VERSION "DNNBNNNYNNNNNNNNNNNNNNNNNNYYYNNNNNNNNNNNNN/4/%%%/4/'%**4NNN///"

NS_ :

BS_:

BU_:  TLCU_L TLCU_R HLCU_R HLCU_L SWCU VCU BCU_F IVI

BO_ 2017 BODY_HLCU_R_UDS_RESP: 8 HLCU_R
 SG_ HLCU_R_uds_resp : 7|64@0+ (1,0) [0|255] ""  IVI

BO_ 2016 BODY_HLCU_R_UDS_REQ: 8 IVI
 SG_ HLCU_R_uds_req : 7|64@0+ (1,0) [0|255] ""  HLCU_R

BO_ 2015 BODY_HLCU_L_UDS_RESP: 8 HLCU_L
 SG_ HLCU_L_uds_resp : 7|64@0+ (1,0) [0|255] ""  IVI

BO_ 2014 BODY_HLCU_L_UDS_REQ: 8 IVI
 SG_ HLCU_L_uds_req : 7|64@0+ (1,0) [0|255] ""  HLCU_L

BO_ 2013 BODY_TLCU_R_UDS_RESP: 8 TLCU_R
 SG_ TLCU_R_uds_resp : 7|64@0+ (1,0) [0|255] ""  IVI

BO_ 2012 BODY_TLCU_R_UDS_REQ: 8 IVI
 SG_ TLCU_R_uds_req : 7|64@0+ (1,0) [0|255] ""  TLCU_R

BO_ 2011 BODY_TLCU_L_UDS_RESP: 8 TLCU_L
 SG_ TLCU_L_uds_resp : 7|64@0+ (1,0) [0|255] ""  IVI

BO_ 2010 BODY_TLCU_L_UDS_REQ: 8 IVI
 SG_ TLCU_L_uds_req : 7|64@0+ (1,0) [0|255] ""  TLCU_L

BO_ 2009 BODY_SWCU_UDS_RESP: 8 SWCU
 SG_ SWCU_uds_resp : 7|64@0+ (1,0) [0|255] ""  IVI

BO_ 2008 BODY_SWCU_UDS_REQ: 8 IVI
 SG_ SWCU_uds_req : 7|64@0+ (1,0) [0|255] ""  SWCU

BO_ 1997 BODY_BCU_F_UDS_RESP: 8 BCU_F
 SG_ BCU_F_uds_resp : 7|64@0+ (1,0) [0|255] ""  IVI

BO_ 1996 BODY_BCU_F_UDS_REQ: 8 IVI
 SG_ BCU_F_uds_req : 7|64@0+ (1,0) [0|255] ""  BCU_F

BO_ 1987 BODY_IVI_UDS_RESP: 8 IVI
 SG_ IVI_uds_resp : 7|64@0+ (1,0) [0|255] ""  IVI

BO_ 1986 BODY_IVI_UDS_REQ: 8 IVI
 SG_ IVI_uds_req : 7|64@0+ (1,0) [0|255] ""  IVI

BO_ 1985 BODY_VCU_UDS_RESP: 8 VCU
 SG_ VCU_uds_resp : 7|64@0+ (1,0) [0|255] ""  IVI

BO_ 1984 BODY_VCU_UDS_REQ: 8 IVI
 SG_ VCU_uds_req : 7|64@0+ (1,0) [0|255] ""  VCU

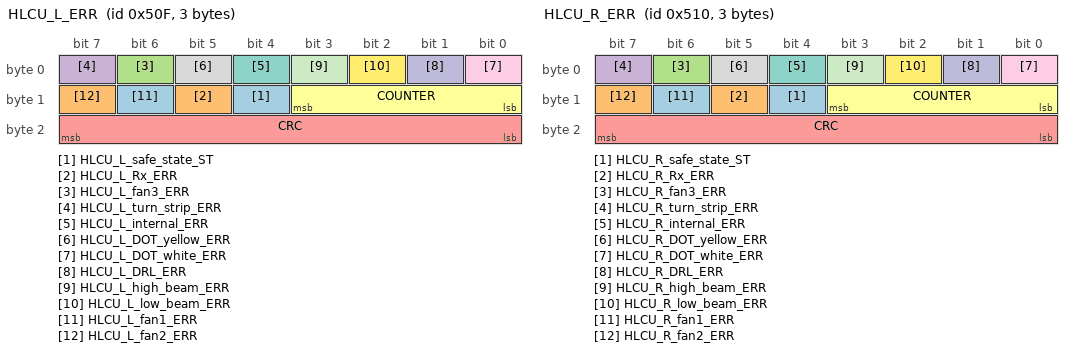
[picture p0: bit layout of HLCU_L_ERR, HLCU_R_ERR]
BO_ 1295 HLCU_L_ERR: 3 HLCU_L
 SG_ HLCU_L_safe_state_ST : 12|1@0+ (1,0) [0|1] ""  VCU,BCU_F
 SG_ HLCU_L_Rx_ERR : 13|1@0+ (1,0) [0|3] ""  VCU,BCU_F
 SG_ HLCU_L_fan3_ERR : 6|1@0+ (1,0) [0|3] ""  VCU,BCU_F
 SG_ HLCU_L_turn_strip_ERR : 7|1@0+ (1,0) [0|3] ""  VCU,BCU_F,IVI
 SG_ CRC : 23|8@0+ (1,0) [0|255] ""  VCU,BCU_F,IVI
 SG_ COUNTER : 11|4@0+ (1,0) [0|15] ""  VCU,BCU_F,IVI
 SG_ HLCU_L_internal_ERR : 4|1@0+ (1,0) [0|3] ""  VCU,BCU_F
 SG_ HLCU_L_DOT_yellow_ERR : 5|1@0+ (1,0) [0|3] ""  VCU,BCU_F,IVI
 SG_ HLCU_L_DOT_white_ERR : 0|1@0+ (1,0) [0|3] ""  VCU,BCU_F
 SG_ HLCU_L_DRL_ERR : 1|1@0+ (1,0) [0|3] ""  VCU,BCU_F
 SG_ HLCU_L_high_beam_ERR : 3|1@0+ (1,0) [0|3] ""  VCU,BCU_F
 SG_ HLCU_L_low_beam_ERR : 2|1@0+ (1,0) [0|3] ""  VCU,BCU_F
 SG_ HLCU_L_fan1_ERR : 14|1@0+ (1,0) [0|3] ""  VCU,BCU_F
 SG_ HLCU_L_fan2_ERR : 15|1@0+ (1,0) [0|3] ""  VCU,BCU_F

BO_ 1296 HLCU_R_ERR: 3 HLCU_R
 SG_ HLCU_R_safe_state_ST : 12|1@0+ (1,0) [0|1] ""  VCU,BCU_F
 SG_ HLCU_R_Rx_ERR : 13|1@0+ (1,0) [0|3] ""  VCU,BCU_F
 SG_ HLCU_R_fan3_ERR : 6|1@0+ (1,0) [0|3] ""  VCU,BCU_F
 SG_ HLCU_R_turn_strip_ERR : 7|1@0+ (1,0) [0|3] ""  VCU,BCU_F,IVI
 SG_ CRC : 23|8@0+ (1,0) [0|255] ""  VCU,BCU_F,IVI
 SG_ COUNTER : 11|4@0+ (1,0) [0|15] ""  VCU,BCU_F,IVI
 SG_ HLCU_R_internal_ERR : 4|1@0+ (1,0) [0|3] ""  VCU,BCU_F
 SG_ HLCU_R_DOT_yellow_ERR : 5|1@0+ (1,0) [0|3] ""  VCU,BCU_F,IVI
 SG_ HLCU_R_DOT_white_ERR : 0|1@0+ (1,0) [0|3] ""  VCU,BCU_F
 SG_ HLCU_R_DRL_ERR : 1|1@0+ (1,0) [0|3] ""  VCU,BCU_F
 SG_ HLCU_R_high_beam_ERR : 3|1@0+ (1,0) [0|3] ""  VCU,BCU_F
 SG_ HLCU_R_low_beam_ERR : 2|1@0+ (1,0) [0|3] ""  VCU,BCU_F
 SG_ HLCU_R_fan1_ERR : 14|1@0+ (1,0) [0|3] ""  VCU,BCU_F
 SG_ HLCU_R_fan2_ERR : 15|1@0+ (1,0) [0|3] ""  VCU,BCU_F

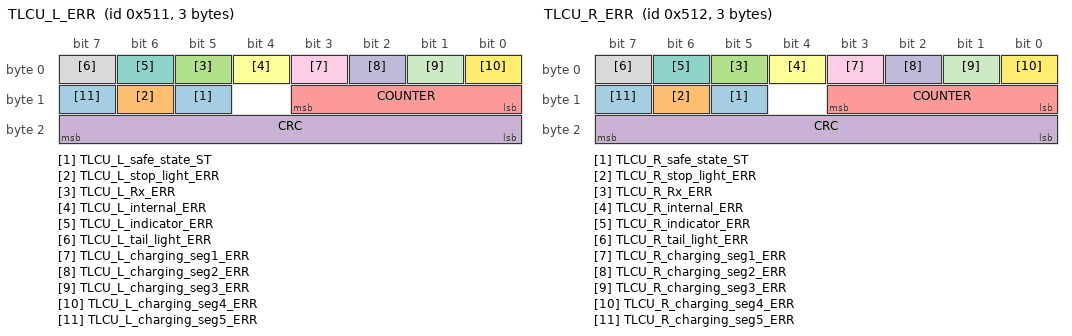
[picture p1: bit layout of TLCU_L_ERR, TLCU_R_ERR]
BO_ 1297 TLCU_L_ERR: 3 TLCU_L
 SG_ TLCU_L_safe_state_ST : 13|1@0+ (1,0) [0|0] ""  VCU,BCU_F
 SG_ TLCU_L_stop_light_ERR : 14|1@0+ (1,0) [0|3] ""  VCU,BCU_F
 SG_ TLCU_L_Rx_ERR : 5|1@0+ (1,0) [0|3] ""  VCU,BCU_F
 SG_ CRC : 23|8@0+ (1,0) [0|255] ""  VCU,BCU_F,IVI
 SG_ COUNTER : 11|4@0+ (1,0) [0|15] ""  VCU,BCU_F,IVI
 SG_ TLCU_L_internal_ERR : 4|1@0+ (1,0) [0|3] ""  VCU,BCU_F
 SG_ TLCU_L_indicator_ERR : 6|1@0+ (1,0) [0|3] ""  VCU,BCU_F,IVI
 SG_ TLCU_L_tail_light_ERR : 7|1@0+ (1,0) [0|3] ""  VCU,BCU_F
 SG_ TLCU_L_charging_seg1_ERR : 3|1@0+ (1,0) [0|3] ""  VCU,BCU_F
 SG_ TLCU_L_charging_seg2_ERR : 2|1@0+ (1,0) [0|3] ""  VCU,BCU_F
 SG_ TLCU_L_charging_seg3_ERR : 1|1@0+ (1,0) [0|3] ""  VCU,BCU_F
 SG_ TLCU_L_charging_seg4_ERR : 0|1@0+ (1,0) [0|3] ""  VCU,BCU_F
 SG_ TLCU_L_charging_seg5_ERR : 15|1@0+ (1,0) [0|3] ""  VCU,BCU_F

BO_ 1298 TLCU_R_ERR: 3 TLCU_R
 SG_ TLCU_R_safe_state_ST : 13|1@0+ (1,0) [0|1] ""  VCU,BCU_F
 SG_ TLCU_R_stop_light_ERR : 14|1@0+ (1,0) [0|3] ""  VCU,BCU_F
 SG_ TLCU_R_Rx_ERR : 5|1@0+ (1,0) [0|3] ""  VCU,BCU_F
 SG_ CRC : 23|8@0+ (1,0) [0|255] ""  VCU,BCU_F,IVI
 SG_ COUNTER : 11|4@0+ (1,0) [0|15] ""  VCU,BCU_F,IVI
 SG_ TLCU_R_internal_ERR : 4|1@0+ (1,0) [0|3] ""  VCU,BCU_F
 SG_ TLCU_R_indicator_ERR : 6|1@0+ (1,0) [0|3] ""  VCU,BCU_F,IVI
 SG_ TLCU_R_tail_light_ERR : 7|1@0+ (1,0) [0|3] ""  VCU,BCU_F
 SG_ TLCU_R_charging_seg1_ERR : 3|1@0+ (1,0) [0|3] ""  VCU,BCU_F
 SG_ TLCU_R_charging_seg2_ERR : 2|1@0+ (1,0) [0|3] ""  VCU,BCU_F
 SG_ TLCU_R_charging_seg3_ERR : 1|1@0+ (1,0) [0|3] ""  VCU,BCU_F
 SG_ TLCU_R_charging_seg4_ERR : 0|1@0+ (1,0) [0|3] ""  VCU,BCU_F
 SG_ TLCU_R_charging_seg5_ERR : 15|1@0+ (1,0) [0|3] ""  VCU,BCU_F

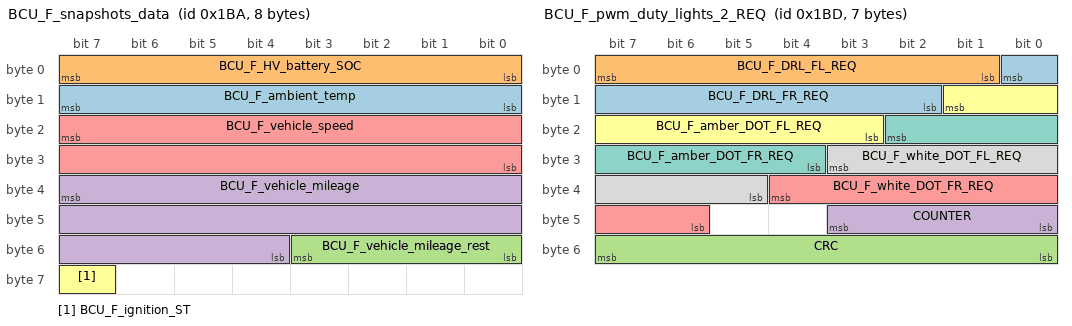
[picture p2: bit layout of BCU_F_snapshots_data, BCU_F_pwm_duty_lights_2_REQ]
BO_ 442 BCU_F_snapshots_data: 8 BCU_F
 SG_ BCU_F_ambient_temp : 15|8@0+ (0.4,-40) [-40|62] "degC"  HLCU_L,HLCU_R,TLCU_L,TLCU_R
 SG_ BCU_F_HV_battery_SOC : 7|8@0+ (1,0) [0|100] "%"  HLCU_L,HLCU_R,TLCU_L,TLCU_R
 SG_ BCU_F_vehicle_mileage_rest : 51|4@0+ (100,0) [0|1000] "m"  HLCU_L,HLCU_R,TLCU_L,TLCU_R
 SG_ BCU_F_vehicle_mileage : 39|20@0+ (1,0) [0|1048575] "km"  HLCU_L,HLCU_R,TLCU_L,TLCU_R
 SG_ BCU_F_vehicle_speed : 23|16@0+ (0.01,0) [0|655.35] "km/h"  HLCU_L,HLCU_R,TLCU_L,TLCU_R
 SG_ BCU_F_ignition_ST : 63|1@0+ (1,0) [0|1] ""  HLCU_L,HLCU_R,TLCU_L,TLCU_R

BO_ 443 BCU_F_light_activation: 4 BCU_F
 SG_ BCU_F_power_supply_ST : 21|1@0+ (1,0) [0|1] ""  HLCU_L,HLCU_R,TLCU_L,TLCU_R
 SG_ CRC : 31|8@0+ (1,0) [0|255] ""  HLCU_L,HLCU_R,TLCU_L,TLCU_R,IVI,VCU
 SG_ COUNTER : 19|4@0+ (1,0) [0|15] ""  HLCU_L,HLCU_R,TLCU_L,TLCU_R,IVI,VCU
 SG_ BCU_F_white_DOT_FR_EN : 8|1@0+ (1,0) [0|1] ""  HLCU_R
 SG_ BCU_F_white_DOT_FL_EN : 9|1@0+ (1,0) [0|1] ""  HLCU_L
 SG_ BCU_F_tail_light_RR_EN : 0|1@0+ (1,0) [0|1] ""  TLCU_R
 SG_ BCU_F_tail_light_RL_EN : 1|1@0+ (1,0) [0|1] ""  TLCU_L
 SG_ BCU_F_indicator_RR_EN : 10|1@0+ (1,0) [0|1] ""  TLCU_R,IVI,VCU,M2M
 SG_ BCU_F_indicator_RL_EN : 11|1@0+ (1,0) [0|1] ""  TLCU_L,IVI,VCU,M2M
 SG_ BCU_F_indicator_FR_EN : 14|1@0+ (1,0) [0|1] ""  HLCU_R,IVI,VCU,M2M
 SG_ BCU_F_indicator_FL_EN : 15|1@0+ (1,0) [0|1] ""  HLCU_L,IVI,VCU,M2M
 SG_ BCU_F_DRL_FR_EN : 2|1@0+ (1,0) [0|1] ""  HLCU_R
 SG_ BCU_F_DRL_FL_EN : 3|1@0+ (1,0) [0|1] ""  HLCU_L
 SG_ BCU_F_amber_DOT_FL_EN : 23|1@0+ (1,0) [0|1] ""  HLCU_L,IVI,VCU,M2M
 SG_ BCU_F_amber_DOT_FR_EN : 22|1@0+ (1,0) [0|1] ""  HLCU_R,IVI,VCU,M2M
 SG_ BCU_F_low_beam_FL_EN : 5|1@0+ (1,0) [0|1] ""  HLCU_L
 SG_ BCU_F_high_beam_FR_EN : 6|1@0+ (1,0) [0|1] ""  HLCU_R
 SG_ BCU_F_indicator_MR_EN : 12|1@0+ (1,0) [0|1] ""  IVI,VCU,M2M
 SG_ BCU_F_indicator_ML_EN : 13|1@0+ (1,0) [0|1] ""  IVI,VCU,M2M
 SG_ BCU_F_low_beam_FR_EN : 4|1@0+ (1,0) [0|1] ""  HLCU_R
 SG_ BCU_F_high_beam_FL_EN : 7|1@0+ (1,0) [0|1] ""  HLCU_L

BO_ 445 BCU_F_pwm_duty_lights_2_REQ: 7 BCU_F
 SG_ BCU_F_DRL_FR_REQ : 0|7@0+ (1,0) [0|100] "%"  HLCU_R
 SG_ BCU_F_DRL_FL_REQ : 7|7@0+ (1,0) [0|100] "%"  HLCU_L
 SG_ CRC : 55|8@0+ (1,0) [0|255] ""  HLCU_L,HLCU_R
 SG_ COUNTER : 43|4@0+ (1,0) [0|15] ""  HLCU_L,HLCU_R
 SG_ BCU_F_white_DOT_FR_REQ : 36|7@0+ (1,0) [0|100] "%"  HLCU_R
 SG_ BCU_F_amber_DOT_FL_REQ : 9|7@0+ (1,0) [0|100] "%"  HLCU_L
 SG_ BCU_F_amber_DOT_FR_REQ : 18|7@0+ (1,0) [0|100] "%"  HLCU_R
 SG_ BCU_F_white_DOT_FL_REQ : 27|7@0+ (1,0) [0|100] "%"  HLCU_L

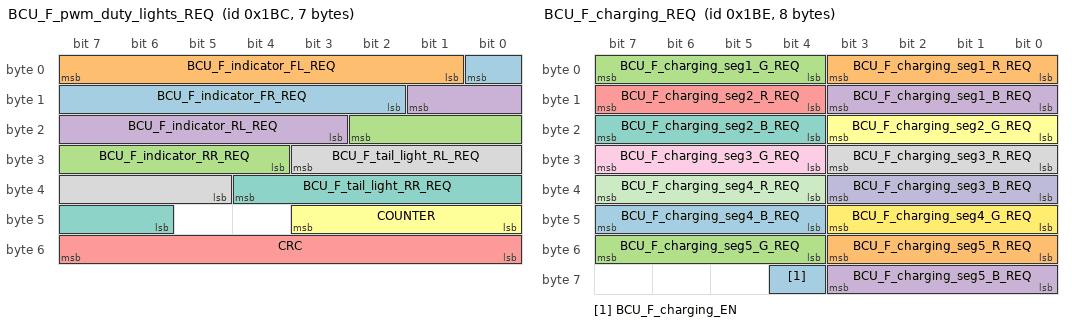
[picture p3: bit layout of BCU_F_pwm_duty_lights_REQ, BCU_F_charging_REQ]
BO_ 444 BCU_F_pwm_duty_lights_REQ: 7 BCU_F
 SG_ BCU_F_indicator_FR_REQ : 0|7@0+ (1,0) [0|100] "%"  HLCU_R
 SG_ BCU_F_indicator_FL_REQ : 7|7@0+ (1,0) [0|100] "%"  HLCU_L
 SG_ BCU_F_indicator_RR_REQ : 18|7@0+ (1,0) [0|100] "%"  TLCU_R
 SG_ BCU_F_indicator_RL_REQ : 9|7@0+ (1,0) [0|100] "%"  TLCU_L
 SG_ CRC : 55|8@0+ (1,0) [0|255] ""  TLCU_L,TLCU_R,HLCU_L,HLCU_R
 SG_ COUNTER : 43|4@0+ (1,0) [0|15] ""  TLCU_L,TLCU_R,HLCU_L,HLCU_R
 SG_ BCU_F_tail_light_RR_REQ : 36|7@0+ (1,0) [0|100] "%"  TLCU_R
 SG_ BCU_F_tail_light_RL_REQ : 27|7@0+ (1,0) [0|100] "%"  TLCU_L

BO_ 446 BCU_F_charging_REQ: 8 BCU_F
 SG_ BCU_F_charging_EN : 60|1@0+ (1,0) [0|1] ""  TLCU_L,TLCU_R,M2M
 SG_ BCU_F_charging_seg1_R_REQ : 3|4@0+ (7,0) [0|100] "%"  TLCU_L,TLCU_R,M2M
 SG_ BCU_F_charging_seg1_G_REQ : 7|4@0+ (7,0) [0|100] "%"  TLCU_L,TLCU_R,M2M
 SG_ BCU_F_charging_seg1_B_REQ : 11|4@0+ (7,0) [0|100] "%"  TLCU_L,TLCU_R,M2M
 SG_ BCU_F_charging_seg2_R_REQ : 15|4@0+ (7,0) [0|100] "%"  TLCU_L,TLCU_R,M2M
 SG_ BCU_F_charging_seg2_G_REQ : 19|4@0+ (7,0) [0|100] "%"  TLCU_L,TLCU_R,M2M
 SG_ BCU_F_charging_seg2_B_REQ : 23|4@0+ (7,0) [0|100] "%"  TLCU_L,TLCU_R,M2M
 SG_ BCU_F_charging_seg3_R_REQ : 27|4@0+ (7,0) [0|100] "%"  TLCU_L,TLCU_R,M2M
 SG_ BCU_F_charging_seg3_G_REQ : 31|4@0+ (7,0) [0|100] "%"  TLCU_L,TLCU_R,M2M
 SG_ BCU_F_charging_seg3_B_REQ : 35|4@0+ (7,0) [0|100] "%"  TLCU_L,TLCU_R,M2M
 SG_ BCU_F_charging_seg4_R_REQ : 39|4@0+ (7,0) [0|100] "%"  TLCU_L,TLCU_R,M2M
 SG_ BCU_F_charging_seg4_G_REQ : 43|4@0+ (7,0) [0|100] "%"  TLCU_L,TLCU_R,M2M
 SG_ BCU_F_charging_seg4_B_REQ : 47|4@0+ (7,0) [0|100] "%"  TLCU_L,TLCU_R,M2M
 SG_ BCU_F_charging_seg5_R_REQ : 51|4@0+ (7,0) [0|100] "%"  TLCU_L,TLCU_R,M2M
 SG_ BCU_F_charging_seg5_G_REQ : 55|4@0+ (7,0) [0|100] "%"  TLCU_L,TLCU_R,M2M
 SG_ BCU_F_charging_seg5_B_REQ : 59|4@0+ (7,0) [0|100] "%"  TLCU_L,TLCU_R,M2M

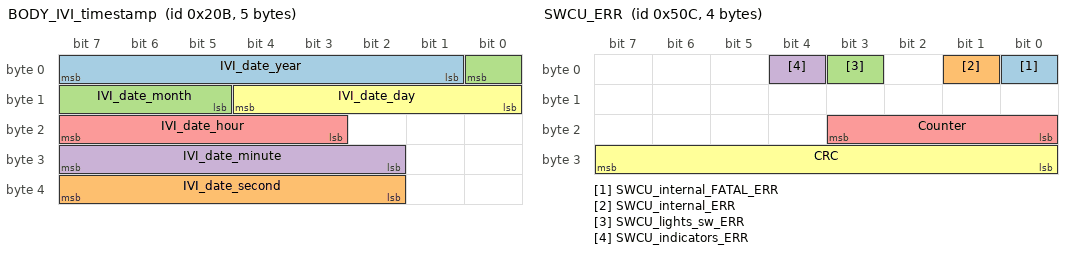
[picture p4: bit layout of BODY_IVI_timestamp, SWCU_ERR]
BO_ 523 BODY_IVI_timestamp: 5 IVI
 SG_ IVI_date_year : 7|7@0+ (1,2000) [2000|2127] "year"  VCU,M2M,SWCU,BCU_F,HLCU_L,HLCU_R,TLCU_L,TLCU_R
 SG_ IVI_date_second : 39|6@0+ (1,0) [0|59] "second"  VCU,M2M,SWCU,BCU_F,HLCU_L,HLCU_R,TLCU_L,TLCU_R
 SG_ IVI_date_month : 0|4@0+ (1,0) [0|12] "month"  VCU,M2M,SWCU,BCU_F,HLCU_L,HLCU_R,TLCU_L,TLCU_R
 SG_ IVI_date_minute : 31|6@0+ (1,0) [0|59] "minute"  VCU,M2M,SWCU,BCU_F,HLCU_L,HLCU_R,TLCU_L,TLCU_R
 SG_ IVI_date_hour : 23|5@0+ (1,0) [0|23] "hour"  VCU,M2M,SWCU,BCU_F,HLCU_L,HLCU_R,TLCU_L,TLCU_R
 SG_ IVI_date_day : 12|5@0+ (1,0) [0|31] "day"  VCU,M2M,SWCU,BCU_F,HLCU_L,HLCU_R,TLCU_L,TLCU_R

BO_ 1292 SWCU_ERR: 4 SWCU
 SG_ SWCU_internal_FATAL_ERR : 0|1@0+ (1,0) [0|1] "" VCU,IVI,M2M
 SG_ SWCU_internal_ERR : 1|1@0+ (1,0) [0|1] "" VCU,IVI,M2M
 SG_ SWCU_lights_sw_ERR : 3|1@0+ (1,0) [0|1] "" VCU,IVI,M2M
 SG_ SWCU_indicators_ERR : 4|1@0+ (1,0) [0|1] "" VCU,IVI,M2M
 SG_ Counter : 19|4@0+ (1,0)[0|15] "" VCU,IVI,M2M
 SG_ CRC : 31|8@0+ (1,0)[0|255] "" VCU,IVI,M2M

BO_ 1579 OFFCAR_VCU_XCP: 8 OFFCAR_VCU
 SG_ OFFCAR_VCU_xcp : 0|64@1+ (1,0) [0|0] ""  VCU

BO_ 1578 VCU_XCP: 8 VCU
 SG_ VCU_xcp : 0|64@1+ (1,0) [0|0] ""  OFFCAR_VCU

BO_ 1573 OFFCAR_SWCU_XCP: 8 OFFCAR_VCU
 SG_ OFFCAR_SWCU_xcp : 0|64@1+ (1,0) [0|0] ""  SWCU

BO_ 1572 SWCU_XCP: 8 SWCU
 SG_ SWCU_xcp : 0|64@1+ (1,0) [0|0] ""  OFFCAR_VCU

BO_ 1553 OFFCAR_BCU_F_XCP: 8 OFFCAR_VCU
 SG_ OFFCAR_BCU_F_xcp : 0|64@1+ (1,0) [0|0] ""  BCU_F

BO_ 1552 BCU_F_XCP: 8 BCU_F
 SG_ BCU_F_xcp : 0|64@1+ (1,0) [0|0] ""  OFFCAR_VCU

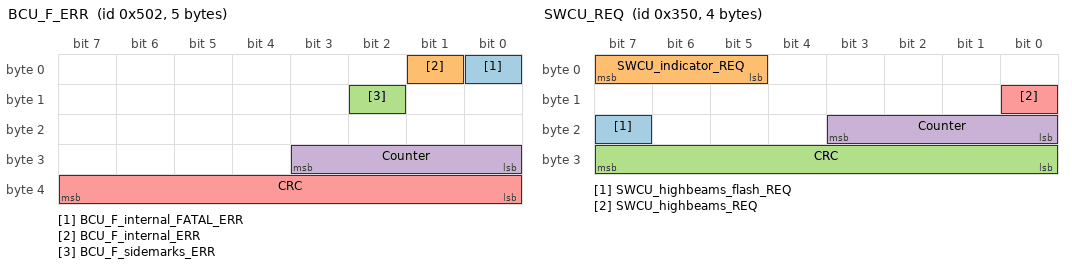
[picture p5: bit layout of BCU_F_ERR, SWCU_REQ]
BO_ 1282 BCU_F_ERR: 5 BCU_F
 SG_ BCU_F_internal_FATAL_ERR : 0|1@0+ (1,0) [0|1] ""  VCU,IVI,M2M
 SG_ BCU_F_internal_ERR : 1|1@0+ (1,0) [0|1] ""  VCU,IVI,M2M
 SG_ BCU_F_sidemarks_ERR : 10|1@0+ (1,0) [0|1] ""  VCU,IVI,M2M
 SG_ Counter : 27|4@0+ (1,0) [0|15] ""  VCU,IVI,M2M
 SG_ CRC : 39|8@0+ (1,0) [0|255] ""  VCU,IVI,M2M

BO_ 1045 VCU_version_info: 8 VCU
 SG_ VCU_FW_commit_hash m1 : 39|32@0+ (1,0) [0|0] ""  OFFCAR_VCU,M2M
 SG_ VCU_BL_commit_hash m0 : 39|32@0+ (1,0) [0|0] ""  OFFCAR_VCU,M2M
 SG_ VCU_version_dbc m3 : 63|8@0+ (1,0) [0|255] ""  OFFCAR_VCU,M2M
 SG_ VCU_BL_version_dev m0 : 5|1@0+ (1,0) [0|1] ""  OFFCAR_VCU,M2M
 SG_ VCU_FW_version_dev m1 : 5|1@0+ (1,0) [0|1] ""  OFFCAR_VCU,M2M
 SG_ VCU_HW_version_patch m2 : 31|8@0+ (1,0) [0|16777215] ""  OFFCAR_VCU,M2M
 SG_ VCU_HW_version_minor m2 : 23|8@0+ (1,0) [0|16777215] ""  OFFCAR_VCU,M2M
 SG_ VCU_HW_version_major m2 : 15|8@0+ (1,0) [0|16777215] ""  OFFCAR_VCU,M2M
 SG_ VCU_FW_version_patch m1 : 31|8@0+ (1,0) [0|16777215] ""  OFFCAR_VCU,M2M
 SG_ VCU_FW_version_minor m1 : 23|8@0+ (1,0) [0|16777215] ""  OFFCAR_VCU,M2M
 SG_ VCU_FW_version_major m1 : 15|8@0+ (1,0) [0|16777215] ""  OFFCAR_VCU,M2M
 SG_ VCU_BL_version_patch m0 : 31|8@0+ (1,0) [0|16777215] ""  OFFCAR_VCU,M2M
 SG_ VCU_BL_version_minor m0 : 23|8@0+ (1,0) [0|16777215] ""  OFFCAR_VCU,M2M
 SG_ VCU_BL_version_major m0 : 15|8@0+ (1,0) [0|16777215] ""  OFFCAR_VCU,M2M
 SG_ VCU_version_serial_number m3 : 15|48@0+ (1,0) [0|65535] ""  OFFCAR_VCU,M2M
 SG_ VCU_version_info_MUX M : 7|2@0+ (1,0) [0|3] ""  OFFCAR_VCU,M2M

BO_ 1032 BCU_F_version_info: 8 BCU_F
 SG_ BCU_F_FW_commit_hash m1 : 39|32@0+ (1,0) [0|0] ""  OFFCAR_VCU,M2M
 SG_ BCU_F_BL_commit_hash m0 : 39|32@0+ (1,0) [0|0] ""  OFFCAR_VCU,M2M
 SG_ BCU_F_version_dbc m3 : 63|8@0+ (1,0) [0|255] ""  OFFCAR_VCU,M2M
 SG_ BCU_F_BL_version_dev m0 : 5|1@0+ (1,0) [0|1] ""  OFFCAR_VCU,M2M
 SG_ BCU_F_FW_version_dev m1 : 5|1@0+ (1,0) [0|1] ""  OFFCAR_VCU,M2M
 SG_ BCU_F_HW_version_patch m2 : 31|8@0+ (1,0) [0|16777215] ""  OFFCAR_VCU,M2M
 SG_ BCU_F_HW_version_minor m2 : 23|8@0+ (1,0) [0|16777215] ""  OFFCAR_VCU,M2M
 SG_ BCU_F_HW_version_major m2 : 15|8@0+ (1,0) [0|16777215] ""  OFFCAR_VCU,M2M
 SG_ BCU_F_FW_version_patch m1 : 31|8@0+ (1,0) [0|16777215] ""  OFFCAR_VCU,M2M
 SG_ BCU_F_FW_version_minor m1 : 23|8@0+ (1,0) [0|16777215] ""  OFFCAR_VCU,M2M
 SG_ BCU_F_FW_version_major m1 : 15|8@0+ (1,0) [0|16777215] ""  OFFCAR_VCU,M2M
 SG_ BCU_F_BL_version_patch m0 : 31|8@0+ (1,0) [0|16777215] ""  OFFCAR_VCU,M2M
 SG_ BCU_F_BL_version_minor m0 : 23|8@0+ (1,0) [0|16777215] ""  OFFCAR_VCU,M2M
 SG_ BCU_F_BL_version_major m0 : 15|8@0+ (1,0) [0|16777215] ""  OFFCAR_VCU,M2M
 SG_ BCU_F_version_serial_number m3 : 15|48@0+ (1,0) [0|65535] ""  OFFCAR_VCU,M2M
 SG_ BCU_F_version_info_MUX M : 7|2@0+ (1,0) [0|3] ""  OFFCAR_VCU,M2M

BO_ 1047 IVI_version_info: 8 IVI
 SG_ IVI_version_dbc m3 : 63|8@0+ (1,0) [0|0] ""  OFFCAR_VCU,M2M
 SG_ IVI_version_serial_number m3 : 15|48@0+ (1,0) [0|0] ""  OFFCAR_VCU,M2M
 SG_ IVI_HW_version_patch m2 : 31|8@0+ (1,0) [0|0] ""  OFFCAR_VCU,M2M
 SG_ IVI_HW_version_minor m2 : 23|8@0+ (1,0) [0|0] ""  OFFCAR_VCU,M2M
 SG_ IVI_HW_version_major m2 : 15|8@0+ (1,0) [0|0] ""  OFFCAR_VCU,M2M
 SG_ IVI_FW_commit_hash m1 : 39|32@0+ (1,0) [0|0] ""  OFFCAR_VCU,M2M
 SG_ IVI_FW_version_patch m1 : 31|8@0+ (1,0) [0|0] ""  OFFCAR_VCU,M2M
 SG_ IVI_FW_version_minor m1 : 23|8@0+ (1,0) [0|0] ""  OFFCAR_VCU,M2M
 SG_ IVI_FW_version_major m1 : 15|8@0+ (1,0) [0|0] ""  OFFCAR_VCU,M2M
 SG_ IVI_FW_version_dev m1 : 5|1@0+ (1,0) [0|0] ""  OFFCAR_VCU,M2M
 SG_ IVI_BL_commit_hash m0 : 39|32@0+ (1,0) [0|0] ""  OFFCAR_VCU,M2M
 SG_ IVI_BL_version_patch m0 : 31|8@0+ (1,0) [0|0] ""  OFFCAR_VCU,M2M
 SG_ IVI_BL_version_minor m0 : 23|8@0+ (1,0) [0|0] ""  OFFCAR_VCU,M2M
 SG_ IVI_BL_version_major m0 : 15|8@0+ (1,0) [0|0] ""  OFFCAR_VCU,M2M
 SG_ IVI_BL_version_dev m0 : 5|1@0+ (1,0) [0|0] ""  OFFCAR_VCU,M2M
 SG_ IVI_version_info_MUX M : 7|2@0+ (1,0) [0|0] ""  OFFCAR_VCU,M2M

BO_ 1042 SWCU_version_info: 8 SWCU
 SG_ SWCU_version_dbc m3 : 63|8@0+ (1,0) [0|0] ""  OFFCAR_VCU,M2M
 SG_ SWCU_version_serial_number m3 : 15|48@0+ (1,0) [0|0] ""  OFFCAR_VCU,M2M
 SG_ SWCU_HW_version_patch m2 : 31|8@0+ (1,0) [0|0] ""  OFFCAR_VCU,M2M
 SG_ SWCU_HW_version_minor m2 : 23|8@0+ (1,0) [0|0] ""  OFFCAR_VCU,M2M
 SG_ SWCU_HW_version_major m2 : 15|8@0+ (1,0) [0|0] ""  OFFCAR_VCU,M2M
 SG_ SWCU_FW_commit_hash m1 : 39|32@0+ (1,0) [0|0] ""  OFFCAR_VCU,M2M
 SG_ SWCU_FW_version_patch m1 : 31|8@0+ (1,0) [0|0] ""  OFFCAR_VCU,M2M
 SG_ SWCU_FW_version_minor m1 : 23|8@0+ (1,0) [0|0] ""  OFFCAR_VCU,M2M
 SG_ SWCU_FW_version_major m1 : 15|8@0+ (1,0) [0|0] ""  OFFCAR_VCU,M2M
 SG_ SWCU_FW_version_dev m1 : 5|1@0+ (1,0) [0|0] ""  OFFCAR_VCU,M2M
 SG_ SWCU_BL_commit_hash m0 : 39|32@0+ (1,0) [0|0] ""  OFFCAR_VCU,M2M
 SG_ SWCU_BL_version_patch m0 : 31|8@0+ (1,0) [0|0] ""  OFFCAR_VCU,M2M
 SG_ SWCU_BL_version_minor m0 : 23|8@0+ (1,0) [0|0] ""  OFFCAR_VCU,M2M
 SG_ SWCU_BL_version_major m0 : 15|8@0+ (1,0) [0|0] ""  OFFCAR_VCU,M2M
 SG_ SWCU_BL_version_dev m0 : 5|1@0+ (1,0) [0|0] ""  OFFCAR_VCU,M2M
 SG_ SWCU_version_info_MUX M : 7|2@0+ (1,0) [0|0] ""  OFFCAR_VCU,M2M

BO_ 848 SWCU_REQ: 4 SWCU
 SG_ SWCU_highbeams_flash_REQ : 23|1@0+ (1,0) [0|1] ""  BCU_F,M2M,VCU,IVI
 SG_ SWCU_indicator_REQ : 7|3@0+ (1,0) [0|7] ""  BCU_F,VCU,M2M
 SG_ CRC : 31|8@0+ (1,0) [0|255] ""  IVI,BCU_F,VCU
 SG_ Counter : 19|4@0+ (1,0) [0|15] ""  IVI,BCU_F,VCU
 SG_ SWCU_highbeams_REQ : 8|1@0+ (1,0) [0|1] ""  BCU_F,IVI,VCU,M2M

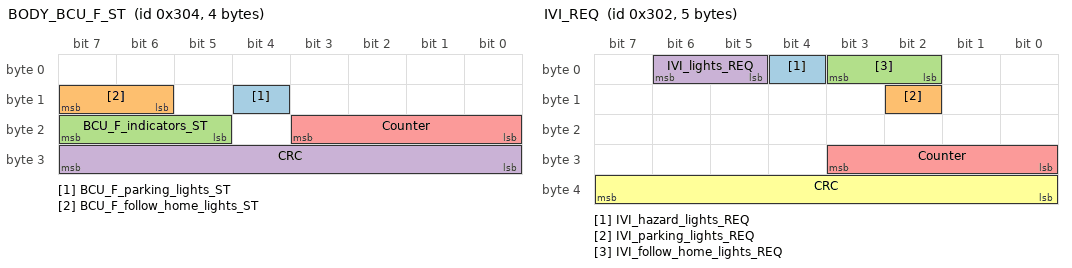
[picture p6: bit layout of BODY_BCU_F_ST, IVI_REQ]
BO_ 772 BODY_BCU_F_ST: 4 BCU_F
 SG_ BCU_F_parking_lights_ST : 12|1@0+ (1,0) [0|1] ""  IVI,VCU
 SG_ BCU_F_follow_home_lights_ST : 15|2@0+ (1,0) [0|3] ""  IVI,M2M
 SG_ BCU_F_indicators_ST : 23|3@0+ (1,0) [0|7] ""  VCU,M2M
 SG_ CRC : 31|8@0+ (1,0) [0|255] ""  IVI,VCU
 SG_ Counter : 19|4@0+ (1,0) [0|15] ""  IVI,VCU

BO_ 770 IVI_REQ: 5 IVI
 SG_ IVI_hazard_lights_REQ : 4|1@0+ (1,0) [0|1] "" BCU_F
 SG_ IVI_parking_lights_REQ : 10|1@0+ (1,0) [0|1] ""  BCU_F
 SG_ IVI_follow_home_lights_REQ : 3|2@0+ (1,0) [0|3] ""  BCU_F,M2M
 SG_ IVI_lights_REQ : 6|2@0+ (1,0) [0|2] ""  BCU_F,M2M
 SG_ Counter : 27|4@0+ (1,0) [0|15] ""  BCU_F,VCU
 SG_ CRC : 39|8@0+ (1,0) [0|255] ""  BCU_F,VCU

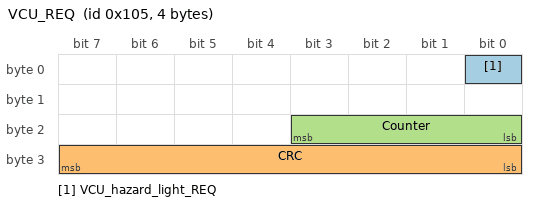
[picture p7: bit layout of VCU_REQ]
BO_ 261 VCU_REQ: 4 VCU
 SG_ VCU_hazard_light_REQ : 0|1@0+ (1,0) [0|1] ""  BCU_F,M2M
 SG_ CRC : 31|8@0+ (1,0) [0|255] ""  BCU_F
 SG_ Counter : 19|4@0+ (1,0) [0|15] ""  BCU_F

BO_ 255 BODY_PCU_vehicle_ST: 8 VCU
 SG_ PCU_vehicle_mileage : 27|20@0+ (1,0) [0|1048575] "km"  SWCU,BCU_F,IVI

CM_ BU_ SWCU "Steering wheel Ecu";
CM_ BU_ BCU_F "Front BCU ";
CM_ BO_ 2017 "HLCU_R diagnostic msg over UDS (Respond)";
CM_ BO_ 2016 "HLCU_R diagnostic msg over UDS (Request)";
CM_ BO_ 2015 "HLCU_L diagnostic msg over UDS (Respond)";
CM_ BO_ 2014 "HLCU_L diagnostic msg over UDS (Request)";
CM_ BO_ 2013 "TLCU_R diagnostic msg over UDS (Respond)";
CM_ BO_ 2012 "TLCU_R diagnostic msg over UDS (Request)";
CM_ BO_ 2011 "TLCU_L diagnostic msg over UDS (Respond)";
CM_ BO_ 2010 "TLCU_L diagnostic msg over UDS (Request)";
CM_ BO_ 2009 "SWCU diagnostic msg over UDS (Respond)";
CM_ BO_ 2008 "SWCU diagnostic msg over UDS (Request)";
CM_ BO_ 1997 "BCU_F diagnostic msg over UDS (Respond)";
CM_ BO_ 1996 "BCU_F diagnostic msg over UDS (Request)";
CM_ BO_ 1987 "IVI diagnostic msg over UDS (Respond)";
CM_ BO_ 1986 "IVI diagnostic msg over UDS (Request)";
CM_ BO_ 1985 "VCU diagnostic msg over UDS (Respond)";
CM_ BO_ 1984 "VCU diagnostic msg over UDS (Request)";
CM_ BO_ 1292 "Steering wheel ECU error message";
CM_ SG_ 1292 SWCU_internal_FATAL_ERR "Initializations failed";
CM_ SG_ 1292 SWCU_internal_ERR "Access to registers, non initialized component; Board component error.";
CM_ SG_ 1292 SWCU_lights_sw_ERR "Lights switch error";
CM_ SG_ 1292 SWCU_indicators_ERR "Indicators switch error";
CM_ SG_ 1292 Counter "Payload protection counter";
CM_ SG_ 1292 CRC "Payload protection CRC";
CM_ BO_ 1282 "Body front ECU error message";
CM_ SG_ 1282 BCU_F_internal_FATAL_ERR "Initializations failed";
CM_ SG_ 1282 BCU_F_internal_ERR "Access to registers, non initialized component; Board component error.";
CM_ SG_ 1282 Counter "Payload protection counter";
CM_ SG_ 1282 CRC "Payload protection CRC";
CM_ SG_ 848 SWCU_highbeams_flash_REQ "Highbeams flash request from steering wheel.";
CM_ SG_ 848 SWCU_indicator_REQ "Indicator request from steering wheel.";
CM_ SG_ 848 SWCU_highbeams_REQ "Highbeams request from steering wheel.";
CM_ SG_ 772 BCU_F_parking_lights_ST "Status of the parking lights.";
CM_ SG_ 772 BCU_F_follow_home_lights_ST "Chosen duration for the follow home lights. ";
CM_ SG_ 770 IVI_parking_lights_REQ "Control of the parking lights.";
CM_ SG_ 770 IVI_follow_home_lights_REQ "Duration for the follow home lights. ";
CM_ SG_ 770 IVI_lights_REQ "Control headlights from IVI";
CM_ SG_ 261 VCU_hazard_light_REQ "Hazard light activation request";
CM_ SG_ 442 BCU_F_ambient_temp "Snapshot information - outside air temperature.";
CM_ SG_ 442 BCU_F_HV_battery_SOC "Snapshot information - state of charge.";
CM_ SG_ 442 BCU_F_vehicle_mileage_rest "Snapshot information - odometer reading (rest). ";
CM_ SG_ 442 BCU_F_vehicle_mileage "Snapshot information - odometer reading. ";
CM_ SG_ 442 BCU_F_vehicle_speed "Snapshot information - vehicle speed. ";
CM_ SG_ 442 BCU_F_ignition_ST "Snapshot information - powertrain status.";
CM_ SG_ 443 BCU_F_power_supply_ST "Power supply state signal.";
CM_ SG_ 443 BCU_F_white_DOT_FR_EN "Front right white DOT control.";
CM_ SG_ 443 BCU_F_white_DOT_FL_EN "Front left white DOT control.";
CM_ SG_ 443 BCU_F_tail_light_RR_EN "Rear right tail light control.";
CM_ SG_ 443 BCU_F_tail_light_RL_EN "Rear left tail light control.";
CM_ SG_ 443 BCU_F_indicator_RR_EN "Rear right indicator control.";
CM_ SG_ 443 BCU_F_indicator_RL_EN "Rear left indicator control.";
CM_ SG_ 443 BCU_F_indicator_FR_EN "Front right indicator control.";
CM_ SG_ 443 BCU_F_indicator_FL_EN "Front left indicator control.";
CM_ SG_ 443 BCU_F_DRL_FR_EN "Front right DRL control.";
CM_ SG_ 443 BCU_F_DRL_FL_EN "Front left DRL control.";
CM_ SG_ 443 BCU_F_amber_DOT_FL_EN "Front left amber DOT control.";
CM_ SG_ 443 BCU_F_amber_DOT_FR_EN "Front right amber DOT control.";
CM_ SG_ 443 BCU_F_low_beam_FL_EN "Front left low beam control.";
CM_ SG_ 443 BCU_F_high_beam_FR_EN "Front right high beam control.";
CM_ SG_ 443 BCU_F_indicator_MR_EN "Right mirror indicator control.";
CM_ SG_ 443 BCU_F_indicator_ML_EN "Left mirror indicator control.";
CM_ SG_ 443 BCU_F_low_beam_FR_EN "Front right low beam control.";
CM_ SG_ 443 BCU_F_high_beam_FL_EN "Front left high beam control.";
CM_ SG_ 445 BCU_F_DRL_FR_REQ "Front right DRL PWM duty rate request.";
CM_ SG_ 445 BCU_F_DRL_FL_REQ "Front left DRL PWM duty rate request.";
CM_ SG_ 445 BCU_F_white_DOT_FR_REQ "Front right white DOT PWM duty rate request.";
CM_ SG_ 445 BCU_F_amber_DOT_FL_REQ "Front left amber DOT PWM duty rate request.";
CM_ SG_ 445 BCU_F_amber_DOT_FR_REQ "Front right amber DOT PWM duty rate request.";
CM_ SG_ 445 BCU_F_white_DOT_FL_REQ "Front left white DOT PWM duty rate request.";
CM_ SG_ 444 BCU_F_indicator_FR_REQ "Front right indicator PWM duty rate request.";
CM_ SG_ 444 BCU_F_indicator_FL_REQ "Front left indicator PWM duty rate request.";
CM_ SG_ 444 BCU_F_indicator_RR_REQ "Rear right indicator PWM duty rate request.";
CM_ SG_ 444 BCU_F_indicator_RL_REQ "Rear left indicator PWM duty rate request.";
CM_ SG_ 444 BCU_F_tail_light_RR_REQ "Rear rigth tail light PWM duty rate request.";
CM_ SG_ 444 BCU_F_tail_light_RL_REQ "Rear left tail light PWM duty rate request.";
CM_ SG_ 446 BCU_F_charging_EN "Charging control.";
CM_ SG_ 446 BCU_F_charging_seg1_R_REQ "R charging segment 1 PWM duty rate request.";
CM_ SG_ 446 BCU_F_charging_seg1_G_REQ "G charging segment 1 PWM duty rate request.";
CM_ SG_ 446 BCU_F_charging_seg1_B_REQ "B charging segment 1 PWM duty rate request.";
CM_ SG_ 446 BCU_F_charging_seg2_R_REQ "R charging segment 2 PWM duty rate request.";
CM_ SG_ 446 BCU_F_charging_seg2_G_REQ "G charging segment 2 PWM duty rate request.";
CM_ SG_ 446 BCU_F_charging_seg2_B_REQ "B charging segment 2 PWM duty rate request.";
CM_ SG_ 446 BCU_F_charging_seg3_R_REQ "R charging segment 3 PWM duty rate request.";
CM_ SG_ 446 BCU_F_charging_seg3_G_REQ "G charging segment 3 PWM duty rate request";
CM_ SG_ 446 BCU_F_charging_seg3_B_REQ "B charging segment 3 PWM duty rate request.";
CM_ SG_ 446 BCU_F_charging_seg4_R_REQ "R charging segment 4 PWM duty rate request";
CM_ SG_ 446 BCU_F_charging_seg4_G_REQ "G charging segment 4 PWM duty rate request";
CM_ SG_ 446 BCU_F_charging_seg4_B_REQ "B charging segment 4 PWM duty rate request";
CM_ SG_ 446 BCU_F_charging_seg5_R_REQ "R charging segment 5 PWM duty rate request";
CM_ SG_ 446 BCU_F_charging_seg5_G_REQ "G charging segment 5 PWM duty rate request";
CM_ SG_ 446 BCU_F_charging_seg5_B_REQ "B charging segment 5 PWM duty rate request";
CM_ SG_ 1295 HLCU_L_safe_state_ST "Safe state status signal.";
CM_ SG_ 1296 HLCU_R_safe_state_ST "Safe state status signal.";
CM_ SG_ 1297 TLCU_L_safe_state_ST "Safe state status signal.";
CM_ SG_ 1298 TLCU_R_safe_state_ST "Safe state status signal.";
CM_ SG_ 772 BCU_F_indicators_ST "Indicators status";

BA_DEF_  "BusJamaID" INT 0 0;
BA_DEF_ SG_  "SigType" ENUM  "Default","Range","RangeSigned","ASCII","Discrete","Control","ReferencePGN","DTC","StringDelimiter","StringLength","StringLengthControl","PayloadCRC","PayloadCounter";
BA_DEF_ SG_  "GenSigEVName" STRING ;
BA_DEF_ SG_  "GenSigILSupport" ENUM  "Yes","No";
BA_DEF_ SG_  "GenSigSendType" ENUM  "Cyclic","OnWrite","OnWriteWithRepetition","OnChange","OnChangeWithRepetition","IfActive","IfActiveWithRepetition","NoSigSendType";
BA_DEF_ SG_  "GenSigStartValue" INT 0 10000;
BA_DEF_ BO_  "GenMsgDelayTime" INT 0 1000;
BA_DEF_ BO_  "GenMsgILSupport" ENUM  "Yes","No";
BA_DEF_ BU_  "NodeLayerModules" STRING ;
BA_DEF_ BU_  "NmStationAddress" INT 0 255;
BA_DEF_ BO_  "GenMsgSendType" ENUM  "Cyclic","SendOnRequest","CyclicIfActive","SendOnRequestWithDelay","CyclicAndSendOnRequest","CyclicAndSendOnRequestWithDelay","IfActive","NoMsgSendType";
BA_DEF_ BO_  "GenMsgRequestable" INT 0 1;
BA_DEF_ BO_  "GenMsgCycleTime" INT 0 3600000;
BA_DEF_ BU_  "ILUsed" ENUM  "Yes","No";
BA_DEF_ BO_  "GenMsgNrOfRepetition" INT 0 999999;
BA_DEF_ BO_  "GenMsgCycleTimeFast" INT 2 100000;
BA_DEF_ BO_  "GenMsgPayloadProtected" ENUM "NotProtected","Protected";
BA_DEF_ BO_  "GenMsgPayloadProtectionCRC" ENUM "CRC_ALGORITHM_NOT_USED","CRC_ALGORITHM_8_BIT_J1850","CRC_ALGORITHM_8_BIT_8H2F";
BA_DEF_  "DBName" STRING ;
BA_DEF_  "Baudrate" INT 0 1000000;
BA_DEF_  "BusType" STRING ;
BA_DEF_  "ProtocolType" STRING ;
BA_DEF_DEF_  "BusJamaID" 0;
BA_DEF_DEF_  "SigType" "Default";
BA_DEF_DEF_  "GenSigEVName" "Env@Nodename_@Signame";
BA_DEF_DEF_  "GenSigILSupport" "Yes";
BA_DEF_DEF_  "GenSigSendType" "Cyclic";
BA_DEF_DEF_  "GenSigStartValue" 0;
BA_DEF_DEF_  "GenMsgDelayTime" 1;
BA_DEF_DEF_  "GenMsgILSupport" "Yes";
BA_DEF_DEF_  "NodeLayerModules" "CANoeILNLVector.dll";
BA_DEF_DEF_  "NmStationAddress" 254;
BA_DEF_DEF_  "GenMsgSendType" "Cyclic";
BA_DEF_DEF_  "GenMsgRequestable" 1;
BA_DEF_DEF_  "GenMsgCycleTime" 100;
BA_DEF_DEF_  "ILUsed" "Yes";
BA_DEF_DEF_  "GenMsgNrOfRepetition" 0;
BA_DEF_DEF_  "GenMsgCycleTimeFast" 100;
BA_DEF_DEF_  "DBName" "";
BA_DEF_DEF_  "Baudrate" 500000;
BA_DEF_DEF_  "BusType" "";
BA_DEF_DEF_  "ProtocolType" "J1939";
BA_DEF_DEF_  "GenMsgPayloadProtected" "NotProtected";
BA_DEF_DEF_  "GenMsgPayloadProtectionCRC" "CRC_ALGORITHM_NOT_USED";
BA_ "BusType" "CAN";
BA_ "ProtocolType" "";
BA_ "DBName" "C2_Body";
BA_ "GenMsgCycleTime" BO_ 2017 0;
BA_ "GenMsgSendType" BO_ 2017 1;
BA_ "GenMsgCycleTime" BO_ 2016 0;
BA_ "GenMsgSendType" BO_ 2016 1;
BA_ "GenMsgCycleTime" BO_ 2015 0;
BA_ "GenMsgSendType" BO_ 2015 1;
BA_ "GenMsgCycleTime" BO_ 2014 0;
BA_ "GenMsgSendType" BO_ 2014 1;
BA_ "GenMsgCycleTime" BO_ 2013 0;
BA_ "GenMsgSendType" BO_ 2013 1;
BA_ "GenMsgCycleTime" BO_ 2012 0;
BA_ "GenMsgSendType" BO_ 2012 1;
BA_ "GenMsgCycleTime" BO_ 2011 0;
BA_ "GenMsgSendType" BO_ 2011 1;
BA_ "GenMsgCycleTime" BO_ 2010 0;
BA_ "GenMsgSendType" BO_ 2010 1;
BA_ "GenMsgCycleTime" BO_ 2009 0;
BA_ "GenMsgSendType" BO_ 2009 1;
BA_ "GenMsgCycleTime" BO_ 2008 0;
BA_ "GenMsgSendType" BO_ 2008 1;
BA_ "GenMsgCycleTime" BO_ 1997 0;
BA_ "GenMsgSendType" BO_ 1997 1;
BA_ "GenMsgCycleTime" BO_ 1996 0;
BA_ "GenMsgSendType" BO_ 1996 1;
BA_ "GenMsgCycleTime" BO_ 1987 0;
BA_ "GenMsgSendType" BO_ 1987 1;
BA_ "GenMsgCycleTime" BO_ 1986 0;
BA_ "GenMsgSendType" BO_ 1986 1;
BA_ "GenMsgCycleTime" BO_ 1985 0;
BA_ "GenMsgSendType" BO_ 1985 1;
BA_ "GenMsgCycleTime" BO_ 1984 0;
BA_ "GenMsgSendType" BO_ 1984 1;
BA_ "GenMsgCycleTime" BO_ 523 1000;
BA_ "GenMsgCycleTime" BO_ 1045 1000;
BA_ "GenMsgCycleTime" BO_ 1032 1000;
BA_ "GenMsgCycleTime" BO_ 1047 1000;
BA_ "GenMsgCycleTime" BO_ 1042 1000;
BA_ "GenMsgCycleTime" BO_ 848 300;
BA_ "GenMsgCycleTime" BO_ 772 200;
BA_ "GenMsgSendType" BO_ 770 4;
BA_ "GenMsgNrOfRepetition" BO_ 770 5;
BA_ "GenMsgCycleTimeFast" BO_ 446 20;
BA_ "GenMsgCycleTime" BO_ 446 200;
BA_ "GenMsgNrOfRepetition" BO_ 446 3;
BA_ "GenMsgCycleTimeFast" BO_ 1295 20;
BA_ "GenMsgCycleTime" BO_ 1295 200;
BA_ "GenMsgCycleTimeFast" BO_ 1296 20;
BA_ "GenMsgCycleTime" BO_ 1296 200;
BA_ "GenMsgCycleTimeFast" BO_ 1297 20;
BA_ "GenMsgCycleTime" BO_ 1297 200;
BA_ "GenMsgCycleTimeFast" BO_ 1298 20;
BA_ "GenMsgCycleTime" BO_ 1298 200;
BA_ "SigType" SG_ 1282 CRC 11;
BA_ "SigType" SG_ 1282 Counter 12;
BA_ "GenMsgPayloadProtected" BO_ 1282 1;
BA_ "GenMsgPayloadProtectionCRC" BO_ 1282 2;
BA_ "SigType" SG_ 1292 CRC 11;
BA_ "SigType" SG_ 1292 Counter 12;
BA_ "GenMsgPayloadProtected" BO_ 1292 1;
BA_ "GenMsgPayloadProtectionCRC" BO_ 1292 2;
BA_ "GenMsgCycleTime" BO_ 442 1000;
BA_ "GenMsgCycleTimeFast" BO_ 443 20;
BA_ "GenMsgCycleTime" BO_ 443 200;
BA_ "GenMsgNrOfRepetition" BO_ 443 3;
BA_ "GenSigStartValue" SG_ 442 BCU_F_ambient_temp 100;
BA_ "GenSigSendType" SG_ 443 BCU_F_white_DOT_FR_EN 4;
BA_ "GenSigSendType" SG_ 443 BCU_F_white_DOT_FL_EN 4;
BA_ "GenSigSendType" SG_ 443 BCU_F_tail_light_RR_EN 4;
BA_ "GenSigSendType" SG_ 443 BCU_F_tail_light_RL_EN 4;
BA_ "GenSigSendType" SG_ 443 BCU_F_indicator_RR_EN 4;
BA_ "GenSigSendType" SG_ 443 BCU_F_indicator_RL_EN 4;
BA_ "GenSigSendType" SG_ 443 BCU_F_indicator_FR_EN 4;
BA_ "GenSigSendType" SG_ 443 BCU_F_indicator_FL_EN 4;
BA_ "GenSigSendType" SG_ 443 BCU_F_DRL_FR_EN 4;
BA_ "GenSigSendType" SG_ 443 BCU_F_DRL_FL_EN 4;
BA_ "GenSigSendType" SG_ 443 BCU_F_amber_DOT_FL_EN 4;
BA_ "GenSigSendType" SG_ 443 BCU_F_amber_DOT_FR_EN 4;
BA_ "GenSigSendType" SG_ 443 BCU_F_low_beam_FL_EN 4;
BA_ "GenSigSendType" SG_ 443 BCU_F_high_beam_FR_EN 4;
BA_ "GenSigSendType" SG_ 443 BCU_F_indicator_MR_EN 4;
BA_ "GenSigSendType" SG_ 443 BCU_F_indicator_ML_EN 4;
BA_ "GenSigSendType" SG_ 443 BCU_F_low_beam_FR_EN 4;
BA_ "GenSigSendType" SG_ 443 BCU_F_high_beam_FL_EN 4;
BA_ "GenMsgCycleTimeFast" BO_ 444 20;
BA_ "GenMsgNrOfRepetition" BO_ 444 3;
BA_ "GenMsgCycleTime" BO_ 444 200;
BA_ "GenSigSendType" SG_ 444 BCU_F_indicator_FR_REQ 4;
BA_ "GenSigSendType" SG_ 444 BCU_F_indicator_FL_REQ 4;
BA_ "GenSigSendType" SG_ 444 BCU_F_indicator_RR_REQ 4;
BA_ "GenSigSendType" SG_ 444 BCU_F_indicator_RL_REQ 4;
BA_ "GenSigSendType" SG_ 444 BCU_F_tail_light_RR_REQ 4;
BA_ "GenSigSendType" SG_ 444 BCU_F_tail_light_RL_REQ 4;
BA_ "GenMsgNrOfRepetition" BO_ 445 3;
BA_ "GenMsgCycleTimeFast" BO_ 445 20;
BA_ "GenMsgCycleTime" BO_ 445 200;
BA_ "GenSigSendType" SG_ 445 BCU_F_DRL_FR_REQ 4;
BA_ "GenSigSendType" SG_ 445 BCU_F_DRL_FL_REQ 4;
BA_ "GenSigSendType" SG_ 445 BCU_F_white_DOT_FR_REQ 4;
BA_ "GenSigSendType" SG_ 445 BCU_F_amber_DOT_FL_REQ 4;
BA_ "GenSigSendType" SG_ 445 BCU_F_amber_DOT_FR_REQ 4;
BA_ "GenSigSendType" SG_ 445 BCU_F_white_DOT_FL_REQ 4;
BA_ "BusJamaID" 218279;

VAL_ 772 BCU_F_indicators_ST 4 "Unavailable" 3 "Hazard Lights" 2 "Right" 1 "Left" 0 "Off" ;
VAL_ 1295 HLCU_L_Rx_ERR 1 "Fault detected" 0 "No fault or not yet tested" ;
VAL_ 1295 HLCU_L_fan3_ERR 1 "Fault detected" 0 "No fault or not yet tested" ;
VAL_ 1295 HLCU_L_turn_strip_ERR 1 "Fault detected" 0 "No fault or not yet tested" ;
VAL_ 1295 HLCU_L_internal_ERR 1 "Fault detected" 0 "No fault or not yet tested" ;
VAL_ 1295 HLCU_L_DOT_yellow_ERR 1 "Fault detected" 0 "No fault or not yet tested" ;
VAL_ 1295 HLCU_L_DOT_white_ERR 1 "Fault detected" 0 "No fault or not yet tested" ;
VAL_ 1295 HLCU_L_DRL_ERR 1 "Fault detected" 0 "No fault or not yet tested" ;
VAL_ 1295 HLCU_L_high_beam_ERR 1 "Fault detected" 0 "No fault or not yet tested" ;
VAL_ 1295 HLCU_L_low_beam_ERR 1 "Fault detected" 0 "No fault or not yet tested" ;
VAL_ 1295 HLCU_L_fan1_ERR 1 "Fault detected" 0 "No fault or not yet tested" ;
VAL_ 1295 HLCU_L_fan2_ERR 1 "Fault detected" 0 "No fault or not yet tested" ;
VAL_ 1295 HLCU_L_safe_state_ST 1 "Active" 0 "Inactive" ;
VAL_ 1296 HLCU_R_safe_state_ST 1 "Active" 0 "Inactive" ;
VAL_ 1296 HLCU_R_Rx_ERR 1 "Fault detected" 0 "No fault or not yet tested" ;
VAL_ 1296 HLCU_R_fan3_ERR 1 "Fault detected" 0 "No fault or not yet tested" ;
VAL_ 1296 HLCU_R_turn_strip_ERR 1 "Fault detected" 0 "No fault or not yet tested" ;
VAL_ 1296 HLCU_R_internal_ERR 1 "Fault detected" 0 "No fault or not yet tested" ;
VAL_ 1296 HLCU_R_DOT_yellow_ERR 1 "Fault detected" 0 "No fault or not yet tested" ;
VAL_ 1296 HLCU_R_DOT_white_ERR 1 "Fault detected" 0 "No fault or not yet tested" ;
VAL_ 1296 HLCU_R_DRL_ERR 1 "Fault detected" 0 "No fault or not yet tested" ;
VAL_ 1296 HLCU_R_high_beam_ERR 1 "Fault detected" 0 "No fault or not yet tested" ;
VAL_ 1296 HLCU_R_low_beam_ERR 1 "Fault detected" 0 "No fault or not yet tested" ;
VAL_ 1296 HLCU_R_fan1_ERR 1 "Fault detected" 0 "No fault or not yet tested" ;
VAL_ 1296 HLCU_R_fan2_ERR 1 "Fault detected" 0 "No fault or not yet tested" ;
VAL_ 1297 TLCU_L_safe_state_ST 1 "Active" 0 "Inactive" ;
VAL_ 1297 TLCU_L_stop_light_ERR 1 "Fault detected" 0 "No fault or not yet tested" ;
VAL_ 1297 TLCU_L_Rx_ERR 1 "Fault detected" 0 "No fault or not yet tested" ;
VAL_ 1297 TLCU_L_internal_ERR 1 "Fault detected" 0 "No fault or not yet tested" ;
VAL_ 1297 TLCU_L_indicator_ERR 1 "Fault detected" 0 "No fault or not yet tested" ;
VAL_ 1297 TLCU_L_tail_light_ERR 1 "Fault detected" 0 "No fault or not yet tested" ;
VAL_ 1297 TLCU_L_charging_seg1_ERR 1 "Fault detected" 0 "No fault or not yet tested" ;
VAL_ 1297 TLCU_L_charging_seg2_ERR 1 "Fault detected" 0 "No fault or not yet tested" ;
VAL_ 1297 TLCU_L_charging_seg3_ERR 1 "Fault detected" 0 "No fault or not yet tested" ;
VAL_ 1297 TLCU_L_charging_seg4_ERR 1 "Fault detected" 0 "No fault or not yet tested" ;
VAL_ 1297 TLCU_L_charging_seg5_ERR 1 "Fault detected" 0 "No fault or not yet tested" ;
VAL_ 1298 TLCU_R_safe_state_ST 1 "Active" 0 "Inactive" ;
VAL_ 1298 TLCU_R_stop_light_ERR 1 "Fault detected" 0 "No fault or not yet tested" ;
VAL_ 1298 TLCU_R_Rx_ERR 1 "Fault detected" 0 "No fault or not yet tested" ;
VAL_ 1298 TLCU_R_internal_ERR 1 "Fault detected" 0 "No fault or not yet tested" ;
VAL_ 1298 TLCU_R_indicator_ERR 1 "Fault detected" 0 "No fault or not yet tested" ;
VAL_ 1298 TLCU_R_tail_light_ERR 1 "Fault detected" 0 "No fault or not yet tested" ;
VAL_ 1298 TLCU_R_charging_seg1_ERR 1 "Fault detected" 0 "No fault or not yet tested" ;
VAL_ 1298 TLCU_R_charging_seg2_ERR 1 "Fault detected" 0 "No fault or not yet tested" ;
VAL_ 1298 TLCU_R_charging_seg3_ERR 1 "Fault detected" 0 "No fault or not yet tested" ;
VAL_ 1298 TLCU_R_charging_seg4_ERR 1 "Fault detected" 0 "No fault or not yet tested" ;
VAL_ 1298 TLCU_R_charging_seg5_ERR 1 "Fault detected" 0 "No fault or not yet tested" ;
VAL_ 1292 SWCU_internal_FATAL_ERR 1 "Error" 0 "OK";
VAL_ 1292 SWCU_internal_ERR 1 "Error" 0 "OK";
VAL_ 1292 SWCU_lights_sw_ERR 1 "Error" 0 "OK";
VAL_ 1292 SWCU_indicators_ERR 1 "Error" 0 "OK";
VAL_ 1282 BCU_F_internal_FATAL_ERR 1 "Error" 0 "OK";
VAL_ 1282 BCU_F_internal_ERR 1 "Error" 0 "OK";
VAL_ 1045 VCU_version_info_MUX 3 "VCU serial number" 2 "Hardware version" 1 "Application firmware version" 0 "Bootloader firmware version" ;
VAL_ 1032 BCU_F_version_info_MUX 3 "BCU_F serial number" 2 "Hardware version" 1 "Application firmware version" 0 "Bootloader firmware version" ;
VAL_ 1047 IVI_version_info_MUX 3 "IVI serial number" 2 "Hardware version" 1 "Application firmware version" 0 "Bootloader firmware version" ;
VAL_ 1042 SWCU_version_info_MUX 3 "SWCU serial number" 2 "Hardware version" 1 "Application firmware version" 0 "Bootloader firmware version" ;
VAL_ 848 SWCU_indicator_REQ 4 "3FlashRHS" 3 "3FlashLHS" 2 "RHS" 1 "LHS" 0 "OFF" ;
VAL_ 848 SWCU_highbeams_REQ 1 "ON" 0 "OFF" ;
VAL_ 848 SWCU_highbeams_flash_REQ 1 "ON" 0 "OFF" ;
VAL_ 772 BCU_F_parking_lights_ST 1 "ON " 0 "OFF" ;
VAL_ 772 BCU_F_follow_home_lights_ST 3 "60 seconds" 2 "30 seconds" 1 "10 seconds" 0 "0 seconds" ;
VAL_ 770 IVI_parking_lights_REQ 1 "ON " 0 "OFF" ;
VAL_ 770 IVI_follow_home_lights_REQ 3 "60 seconds" 2 "30 seconds" 1 "10 seconds" 0 "0 seconds" ;
VAL_ 770 IVI_lights_REQ 2 "Low" 1 "Position" 0 "OFF" ;
VAL_ 770 IVI_hazard_lights_REQ 1 "ON" 0 "OFF" ;
VAL_ 261 VCU_hazard_light_REQ 1 "ON" 0 "OFF" ;
VAL_ 442 BCU_F_ignition_ST 1 "ENGAGED" 0 "DISENGAGED" ;
VAL_ 443 BCU_F_power_supply_ST 1 "Shutting down" 0 "Active" ;
VAL_ 443 BCU_F_white_DOT_FR_EN 1 "ON" 0 "OFF" ;
VAL_ 443 BCU_F_white_DOT_FL_EN 1 "ON" 0 "OFF" ;
VAL_ 443 BCU_F_tail_light_RR_EN 1 "ON" 0 "OFF" ;
VAL_ 443 BCU_F_tail_light_RL_EN 1 "ON" 0 "OFF" ;
VAL_ 443 BCU_F_indicator_RR_EN 1 "ON" 0 "OFF" ;
VAL_ 443 BCU_F_indicator_RL_EN 1 "ON" 0 "OFF" ;
VAL_ 443 BCU_F_indicator_FR_EN 1 "ON" 0 "OFF" ;
VAL_ 443 BCU_F_indicator_FL_EN 1 "ON" 0 "OFF" ;
VAL_ 443 BCU_F_DRL_FR_EN 1 "ON" 0 "OFF" ;
VAL_ 443 BCU_F_DRL_FL_EN 1 "ON" 0 "OFF" ;
VAL_ 443 BCU_F_amber_DOT_FL_EN 1 "ON" 0 "OFF" ;
VAL_ 443 BCU_F_amber_DOT_FR_EN 1 "ON" 0 "OFF" ;
VAL_ 443 BCU_F_low_beam_FL_EN 1 "ON" 0 "OFF" ;
VAL_ 443 BCU_F_high_beam_FR_EN 1 "ON" 0 "OFF" ;
VAL_ 443 BCU_F_indicator_MR_EN 1 "ON" 0 "OFF" ;
VAL_ 443 BCU_F_indicator_ML_EN 1 "ON" 0 "OFF" ;
VAL_ 443 BCU_F_low_beam_FR_EN 1 "ON" 0 "OFF" ;
VAL_ 443 BCU_F_high_beam_FL_EN 1 "ON" 0 "OFF" ;
VAL_ 446 BCU_F_charging_EN 1 "ON" 0 "OFF" ;
